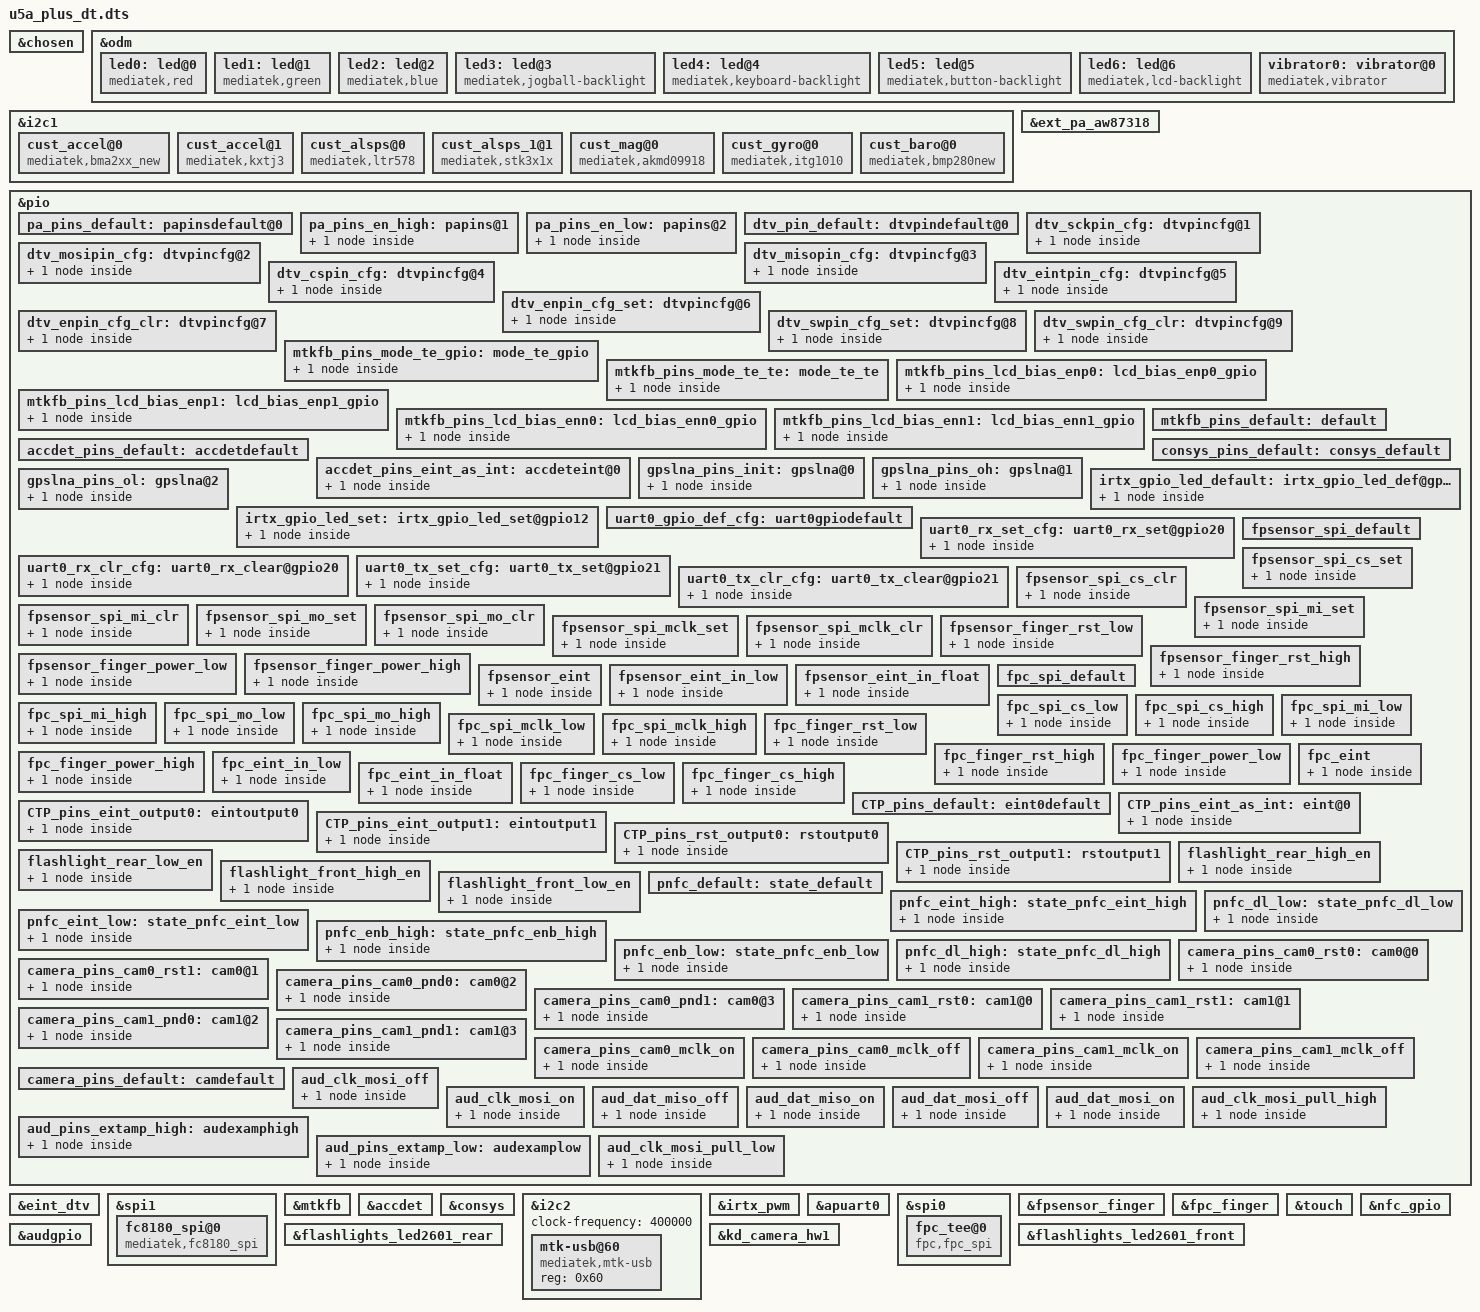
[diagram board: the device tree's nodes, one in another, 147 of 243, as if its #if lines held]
#include <generated/autoconf.h>
/dts-v1/;

#ifdef CONFIG_MTK_DTBO_FEATURE
/plugin/;
#include <dt-bindings/mmc/mt6739-msdc.h>
#include <dt-bindings/pinctrl/mt6739-pinfunc.h>
#else
#include "mt6739.dts"
#endif

/* chosen */
&chosen {
	bootargs = "console=tty0 console=ttyMT0,921600n1 root=/dev/ram initrd=0x44000000,\
0x1000000 loglevel=8 androidboot.selinux=permissive androidboot.hardware=mt6739 initcall_debug=1";
	/* fpga may has no lk, we need to specify display info here */
	/* fb buffer is reserved using this dts by memory node above */

	atag,videolfb-fb_base_l = <0x5e605000>;
	atag,videolfb-fb_base_h = <0>;
	atag,videolfb-islcmfound = <1>;
	atag,videolfb-islcm_inited = <0>;
	atag,videolfb-fps= <6000>;
	atag,videolfb-vramSize= <0x017bb000>;
	atag,videolfb-lcmname= "nt35521_hd_dsi_vdo_truly_nt50358_drv";
};

&odm {
	led0:led@0 {
		compatible = "mediatek,red";
/* Add by rongxiao.deng for 5424735 config charger indicat LED begin */
		led_mode = <3>;
		data = <2>;
/* Add by rongxiao.deng for 5424735 config charger indicat LED end */
		pwm_config = <0 0 0 0 0>;
	};
	led1:led@1 {
		compatible = "mediatek,green";
		led_mode = <0>;
		data = <1>;
		pwm_config = <0 0 0 0 0>;
	};
	led2:led@2 {
		compatible = "mediatek,blue";
		led_mode = <0>;
		data = <1>;
		pwm_config = <0 0 0 0 0>;
	};
	led3:led@3 {
		compatible = "mediatek,jogball-backlight";
		led_mode = <0>;
		data = <1>;
		pwm_config = <0 0 0 0 0>;
	};
	led4:led@4 {
		compatible = "mediatek,keyboard-backlight";
		led_mode = <0>;
		data = <1>;
		pwm_config = <0 0 0 0 0>;
	};
	led5:led@5 {
		compatible = "mediatek,button-backlight";
		led_mode = <0>;
		data = <1>;
		pwm_config = <0 0 0 0 0>;
	};
	led6:led@6 {
		compatible = "mediatek,lcd-backlight";
		led_mode = <5>;
		data = <1>;
		pwm_config = <0 2 0 0 0>;
	};
	vibrator0:vibrator@0 {
		compatible = "mediatek,vibrator";
		vib_timer = <25>;
		vib_limit = <9>;
		vib_vol= <9>;
	};
};
//Begin modified by lanying.he for XR5424729 on 2017/10/20 sensor driver
//Begin modified by lanying.he for XR5592417 on 2017/11/12 sensor 
&i2c1 {
/*  start sensor */
	cust_accel@0 {
		compatible = "mediatek,bma2xx_new";
		//i2c_num	= <1>;
		direction = <6>;
		power_id = <0xffff>;
		power_vol = <0>;
		firlen = <0>;
		is_batch_supported = <0>;
	};
	cust_accel@1 {
		compatible = "mediatek,kxtj3";
		//i2c_num	= <1>;
		direction = <6>;
		power_id = <0xffff>;
		power_vol = <0>;
		firlen = <0>;
		is_batch_supported = <0>;
	};
	cust_alsps@0 {
		compatible = "mediatek,ltr578";
		/*i2c_num = <1>;*/
		i2c_addr = <0x53 0 0 0>;
		polling_mode_ps = <0>;
		polling_mode_als = <1>;
		power_id = <0xffff>;
		power_vol = <0>;
		als_level = <0 328 861 1377 3125 7721 7767 12621 23062 28430 33274 47116 57694 57694 65535>;
		als_value = <0 133 304 502 1004 2005 3058 5005 8008 10010 12000 16000 20000 20000 20000 20000>;
		ps_threshold_high = <26>;
		ps_threshold_low = <21>;
		is_batch_supported_ps = <0>;
		is_batch_supported_als = <0>;
	};
	cust_alsps_1@1 {
		compatible = "mediatek,stk3x1x";
		/*i2c_num = <1>;*/
		i2c_addr = <0x48 0 0 0>;
		polling_mode_ps = <0>;
		polling_mode_als = <1>;
		power_id = <0xffff>;
		power_vol = <0>;
		als_level = <0 328 861 1377 3125 7721 7767 12621 23062 28430 33274 47116 57694 57694 65535>;
		als_value = <0 133 304 502 1004 2005 3058 5005 8008 10010 12000 16000 20000 20000 20000 20000>;
		ps_threshold_high = <26>;
		ps_threshold_low = <21>;
		is_batch_supported_ps = <0>;
		is_batch_supported_als = <0>;
	};
	cust_mag@0 {
		compatible			= "mediatek,akmd09918";
		//i2c_num				= <1>;
		/* i2c_addr			= <0x0C 0 0 0>; */
		direction			= <8>;
		power_id			= <0xffff>;
		power_vol			= <0>;
		/* is_batch_supported		= <0>; */
	};

	cust_gyro@0 {
		compatible			= "mediatek,itg1010";
		//i2c_num				= <1>;
		/* i2c_addr			= <0x68 0 0 0>; */
		direction			= <5>;
		power_id			= <0xffff>;
		power_vol			= <0>;
		firlen				= <0>;
		is_batch_supported		= <0>;
	};

	cust_baro@0 {
		compatible = "mediatek,bmp280new";
		i2c_num = <1>;
		/* i2c_addr = <0x77 0 0 0>; */
		direction = <0>;
		power_id = <0xffff>;
		power_vol = <0>;
		firlen = <32>;
		is_batch_supported = <0>;
	};
/* end sensor */
};

/* Begin added by jinhui.duan.hz for task 5597245 on 20171117,add aw87318 external audio pa driver. */
&ext_pa_aw87318 {
	deb-gpios = <&pio 24 0>;
	pinctrl-names = "pin_default", "en_pin_high", "en_pin_low";
	pinctrl-0 = <&pa_pins_default>;
	pinctrl-1 = <&pa_pins_en_high>;
	pinctrl-2 = <&pa_pins_en_low>;
	status = "okay";
};

&pio {
	pa_pins_default: papinsdefault@0 {
	};
	pa_pins_en_high: papins@1 {
		pins_cmd_dat {
			pins = <PINMUX_GPIO24__FUNC_GPIO24>;
			slew-rate = <1>;
			bias-disable;
			output-high;
		};
	};
	pa_pins_en_low: papins@2 {
		pins_cmd_dat {
			pins = <PINMUX_GPIO24__FUNC_GPIO24>;
			slew-rate = <1>;
			bias-disable;
			output-low;
		};
	};
};
/* End added by jinhui.duan.hz for task 5597245 on 20171117,add aw87318 external audio pa driver. */

/* Begin added by shiqiang.chen.hz for task 5597245 on 20171117,add add fc8180 dtv driver. */
&eint_dtv {
	pinctrl-names = "default", "sck_cfg", "mosi_cfg", "miso_cfg", "cs_cfg", "eint_cfg",
                        "en_cfg_set", "en_cfg_clr", "sw_cfg_set", "sw_cfg_clr";
	pinctrl-0 = <&dtv_pin_default>;
	pinctrl-1 = <&dtv_sckpin_cfg>;
	pinctrl-2 = <&dtv_mosipin_cfg>;
	pinctrl-3 = <&dtv_misopin_cfg>;
	pinctrl-4 = <&dtv_cspin_cfg>;
	pinctrl-5 = <&dtv_eintpin_cfg>;
	pinctrl-6 = <&dtv_enpin_cfg_set>;
	pinctrl-7 = <&dtv_enpin_cfg_clr>;
	pinctrl-8 = <&dtv_swpin_cfg_set>;
	pinctrl-9 = <&dtv_swpin_cfg_clr>;
	status = "okay";
};

&pio {
	dtv_pin_default: dtvpindefault@0 {
	};
	dtv_sckpin_cfg: dtvpincfg@1 {
		pins_cmd_dat {
			pins = <PINMUX_GPIO17__FUNC_SPI1_A_CLK>;
		};
	};
	dtv_mosipin_cfg: dtvpincfg@2 {
		pins_cmd_dat {
			pins = <PINMUX_GPIO19__FUNC_SPI1_A_MO>;
		};
	};
	dtv_misopin_cfg: dtvpincfg@3 {
		pins_cmd_dat {
			pins = <PINMUX_GPIO18__FUNC_SPI1_A_MI>;
		};
	};
	dtv_cspin_cfg: dtvpincfg@4 {
		pins_cmd_dat {
			pins = <PINMUX_GPIO16__FUNC_SPI1_A_CSB>;
		};
	};
	dtv_eintpin_cfg: dtvpincfg@5 {
		pins_cmd_dat {
			pins = <PINMUX_GPIO13__FUNC_GPIO13>;
			slew-rate = <0>;
			bias-disable;
		};
	};
	dtv_enpin_cfg_set: dtvpincfg@6 {
		pins_cmd_dat {
			pins = <PINMUX_GPIO2__FUNC_GPIO2>;
			slew-rate = <1>;
			bias-disable;
			output-high;
		};
	};
	dtv_enpin_cfg_clr: dtvpincfg@7 {
		pins_cmd_dat {
			pins = <PINMUX_GPIO2__FUNC_GPIO2>;
			slew-rate = <1>;
			bias-disable;
			output-low;
		};
	};
	dtv_swpin_cfg_set: dtvpincfg@8 {
		pins_cmd_dat {
			pins = <PINMUX_GPIO28__FUNC_GPIO28>;
			slew-rate = <1>;
			bias-disable;
			output-high;
		};
	};
	dtv_swpin_cfg_clr: dtvpincfg@9 {
		pins_cmd_dat {
			pins = <PINMUX_GPIO28__FUNC_GPIO28>;
			slew-rate = <1>;
			bias-disable;
			output-low;
		};
	};
};

&spi1 {
	#address-cells = <1>;
	#size-cells = <0>;

	fc8180_spi@0 {
		compatible = "mediatek,fc8180_spi";
		reg = <0>;
		spi-max-frequency = <12000000>;
		//netlink-event = <31>;
		status = "okay";
	};
};
/* End added by shiqiang.chen.hz for task 5597245 on 20171117,add add fc8180 dtv driver. */

/* DISPSYS GPIO standardization add by llf for LCD bias */
&pio {

	mtkfb_pins_mode_te_gpio: mode_te_gpio {
		pins_cmd_dat {
			pins = <PINMUX_GPIO84__FUNC_GPIO84>;
		};
	};

	mtkfb_pins_mode_te_te: mode_te_te {
		pins_cmd_dat {
			pins = <PINMUX_GPIO84__FUNC_DSI_TE>;
		};
	};

	mtkfb_pins_lcd_bias_enp0: lcd_bias_enp0_gpio {
		pins_cmd_dat {
			pins = <PINMUX_GPIO28__FUNC_GPIO28>;
			slew-rate = <1>;
			bias-pull-up = <00>;
			output-low;
		};
	};

	mtkfb_pins_lcd_bias_enp1: lcd_bias_enp1_gpio {
		pins_cmd_dat {
			pins = <PINMUX_GPIO28__FUNC_GPIO28>;
			slew-rate = <1>;
			bias-pull-up = <00>;
			output-high;
		};
	};

	mtkfb_pins_lcd_bias_enn0: lcd_bias_enn0_gpio {
                   pins_cmd_dat {
			pins = <PINMUX_GPIO122__FUNC_GPIO122>;
			slew-rate = <1>;
			bias-pull-up = <00>;
			output-low;
                   };
         };

         mtkfb_pins_lcd_bias_enn1: lcd_bias_enn1_gpio {
                   pins_cmd_dat {
			pins = <PINMUX_GPIO122__FUNC_GPIO122>;
			slew-rate = <1>;
			bias-pull-up = <00>;
			output-high;
                   };
         };

	mtkfb_pins_default: default {
	};
};

&mtkfb {
	pinctrl-names = "default", "mode_te_gpio", "mode_te_te",  "lcd_bias_enp0", 
	"lcd_bias_enp1","lcd_bias_enn0", "lcd_bias_enn1";
	pinctrl-0 = <&mtkfb_pins_default>;
	pinctrl-1 = <&mtkfb_pins_mode_te_gpio>;
	pinctrl-2 = <&mtkfb_pins_mode_te_te>;
	pinctrl-3 = <&mtkfb_pins_lcd_bias_enp0>;
	pinctrl-4 = <&mtkfb_pins_lcd_bias_enp1>;
	pinctrl-5 = <&mtkfb_pins_lcd_bias_enn0>;
	pinctrl-6 = <&mtkfb_pins_lcd_bias_enn1>;
	status = "okay";
};/* DISPSYS GPIO standardization add by llf for LCD bias end */


/* accdet start */
&accdet {
	/* accdet micbias voltage: 0x07,2.7v;0x05,2.5v;0x02,1.9v */
	accdet-mic-vol = <6>;
	headset-mode-setting = <0x500 0x500 1 0x1f0 0x800 0x800 0x20 0x44>;
	/* Begin Modified by meng.zhang for task 5424730 on 2017/10/21 */
	accdet-plugout-debounce = <20>;
	/*1:ACC mode, 2:low cost without in bias, 6:low cost with in bias*/
	accdet-mic-mode = <1>;
	/* End Modified by meng.zhang for task 5424730 on 2017/10/21 */
	/* eint_level_trigger: 8,LEVEL_LOW(default);4,LEVEL_HIGH;others,LEVEL_LOW */
	headset-eint-level-pol = <8>;
	/*0--MD_MAX--UP_MAX--DW_MAX*/
	headset-three-key-threshold = <0 80 220 400>;
	headset-three-key-threshold-CDD = <0 121 192 600>;
	/*0--MD_MAX--VOICE_MAX--UP_MAX--DW_MAX*/
	headset-four-key-threshold = <0 58 121 192 400>;
	/* ACCDET GPIO standardization ACC mode no use */
	pinctrl-names = "default", "state_eint_as_int";
	pinctrl-0 = <&accdet_pins_default>;
	pinctrl-1 = <&accdet_pins_eint_as_int>;
	status = "okay";
};
&pio {
	accdet_pins_default: accdetdefault {
	};
	accdet_pins_eint_as_int: accdeteint@0 {
		pins_cmd_dat {
			/* Begin Modified by meng.zhang for task 5424730 on 2017/10/21 */
			pins = <PINMUX_GPIO11__FUNC_GPIO11>;
			/* End Modified by meng.zhang for task 5424730 on 2017/10/21 */
			slew-rate = <0>;
			bias-disable;
		};
	};
};
/* accdet end */
/* CONSYS GPIO standardization */
&pio {
	consys_pins_default: consys_default {
	};
	gpslna_pins_init: gpslna@0 {
		pins_cmd_dat {
			pins = <PINMUX_GPIO118__FUNC_GPIO118>;
			slew-rate = <0>;
			bias-disable;
			output-low;
		};
	};
	gpslna_pins_oh: gpslna@1 {
		pins_cmd_dat {
			pins = <PINMUX_GPIO118__FUNC_GPIO118>;
			slew-rate = <1>;
			output-high;
		};
	};
	gpslna_pins_ol: gpslna@2 {
		pins_cmd_dat {
			pins = <PINMUX_GPIO118__FUNC_GPIO118>;
			slew-rate = <1>;
			output-low;
		};
	};
};
&consys {
	pinctrl-names = "default", "gps_lna_state_init", "gps_lna_state_oh", "gps_lna_state_ol";
	pinctrl-0 = <&consys_pins_default>;
	pinctrl-1 = <&gpslna_pins_init>;
	pinctrl-2 = <&gpslna_pins_oh>;
	pinctrl-3 = <&gpslna_pins_ol>;
	status = "okay";
};
&i2c2 {
	#address-cells = <1>;
	#size-cells = <0>;
	clock-frequency = <400000>;

	mtk-usb@60 {
		compatible = "mediatek,mtk-usb";
		reg = <0x60>;
		status = "okay";
	};
};

/* IRTX GPIO Start */
&irtx_pwm {
	pinctrl-names = "irtx_gpio_led_default", "irtx_gpio_led_set";
	pinctrl-0 = <&irtx_gpio_led_default>;
	pinctrl-1 = <&irtx_gpio_led_set>;
	status = "okay";
};
&pio {
	/* IRTX GPIO Settings -Start */
	/* default: GPIO0, output, high */
	irtx_gpio_led_default:irtx_gpio_led_def@gpio12 {
		pins_cmd_dat {
			pins = <PINMUX_GPIO12__FUNC_GPIO12>;
			slew-rate = <1>;
			bias-disable;
			output-low;
			input-schmitt-enable = <0>;
		};
	};

	irtx_gpio_led_set:irtx_gpio_led_set@gpio12 {
		pins_cmd_dat {
			pins = <PINMUX_GPIO12__FUNC_PWM1>;
			slew-rate = <1>;
			output-high;
		};
	};
}; /* IRTX GPIO Settings -End */

/* UART GPIO */
&apuart0 {
	pinctrl-names = "uart0_gpio_default",
			"uart0_rx_set",
			"uart0_rx_clear",
			"uart0_tx_set",
			"uart0_tx_clear";
	pinctrl-0 = <&uart0_gpio_def_cfg>;
	pinctrl-1 = <&uart0_rx_set_cfg>;
	pinctrl-2 = <&uart0_rx_clr_cfg>;
	pinctrl-3 = <&uart0_tx_set_cfg>;
	pinctrl-4 = <&uart0_tx_clr_cfg>;
	status = "okay";
};

&pio {
	/* UART GPIO Settings - Start */
	/* UART0: rx set, rx clear, tx clear, tx clear*/
	uart0_gpio_def_cfg:uart0gpiodefault {

	};
	uart0_rx_set_cfg:uart0_rx_set@gpio20 {
		pins_cmd_dat {
			pins = <PINMUX_GPIO20__FUNC_UART0RX>;
		};
	};
	uart0_rx_clr_cfg:uart0_rx_clear@gpio20 {
		pins_cmd_dat {
			pins = <PINMUX_GPIO20__FUNC_GPIO20>;
			slew-rate = <1>;
			output-high;
		};
	};
	uart0_tx_set_cfg:uart0_tx_set@gpio21 {
		pins_cmd_dat {
			pins = <PINMUX_GPIO21__FUNC_UART0TX>;
		};
	};
	uart0_tx_clr_cfg:uart0_tx_clear@gpio21 {
		pins_cmd_dat {
			pins = <PINMUX_GPIO21__FUNC_GPIO21>;
			slew-rate = <1>;
			output-high;
		};
	};
};/* UART GPIO end */

/* FINGERPRINT start */
/*Begin added by zhihua.fang for u5a fpsensor on 2017/11/1*/

//according to fps fae mtxxx.dts
&spi0 {
	#address-cells = <1>;     
	#size-cells = <0>;
   fpc_tee@0 {
       		compatible = "fpc,fpc_spi";
       		reg = <0>;
       		spi-max-frequency = <10000000>;
       		netlink-event = <31>;
			fpc,enable-wakeup;
       		status = "okay";
    	};
};

&fpsensor_finger {

        pinctrl-names = "fpsensor_spi_default", "fpsensor_spi_cs_set","fpsensor_spi_cs_clr","fpsensor_spi_mi_set","fpsensor_spi_mi_clr",
			"fpsensor_spi_mo_set","fpsensor_spi_mo_clr","fpsensor_spi_mclk_set","fpsensor_spi_mclk_clr",
			"fpsensor_finger_rst_low","fpsensor_finger_rst_high","fpsensor_finger_power_low","fpsensor_finger_power_high",
	                "fpsensor_eint","fpsensor_eint_in_low","fpsensor_eint_in_float";	
	pinctrl-0 = <&fpsensor_spi_default>;
	pinctrl-1 = <&fpsensor_spi_cs_set>;
	pinctrl-2 = <&fpsensor_spi_cs_clr>;
	pinctrl-3 = <&fpsensor_spi_mi_set>;
	pinctrl-4 = <&fpsensor_spi_mi_clr>;
	pinctrl-5 = <&fpsensor_spi_mo_set>;
	pinctrl-6 = <&fpsensor_spi_mo_clr>;
	pinctrl-7 = <&fpsensor_spi_mclk_set>;
	pinctrl-8 = <&fpsensor_spi_mclk_clr>;	
	pinctrl-9 = <&fpsensor_finger_rst_low>;
	pinctrl-10 = <&fpsensor_finger_rst_high>;
	pinctrl-11 = <&fpsensor_finger_power_low>;
	pinctrl-12 = <&fpsensor_finger_power_high>;	
	pinctrl-13 = <&fpsensor_eint>;
	pinctrl-14 = <&fpsensor_eint_in_low>;
	pinctrl-15 = <&fpsensor_eint_in_float>;
	status = "okay";
};

&pio {
	fpsensor_spi_default: fpsensor_spi_default {
	};

	fpsensor_spi_cs_set: fpsensor_spi_cs_set {
		pins_cmd_dat {
                        pins = <PINMUX_GPIO31__FUNC_SPI0_A_CSB>;
			output-enable;
		};
	};
	fpsensor_spi_cs_clr: fpsensor_spi_cs_clr {
		pins_cmd_dat {
                        pins = <PINMUX_GPIO31__FUNC_GPIO31>;
			slew-rate = <1>;
			output-high;
		};
	};	

	fpsensor_spi_mi_set: fpsensor_spi_mi_set {
		pins_cmd_dat {
                        pins = <PINMUX_GPIO33__FUNC_SPI0_A_MI>;
			input-enable;
		};
		
	};
	fpsensor_spi_mi_clr: fpsensor_spi_mi_clr {
		pins_cmd_dat {
                        pins = <PINMUX_GPIO33__FUNC_GPIO33>;
			slew-rate = <1>;
			output-high;
		};
	};	

	fpsensor_spi_mo_set: fpsensor_spi_mo_set {
		pins_cmd_dat {
                        pins = <PINMUX_GPIO34__FUNC_SPI0_A_MO>;
			input-enable;
		};

	};
	fpsensor_spi_mo_clr: fpsensor_spi_mo_clr {
		pins_cmd_dat {
			pins = <PINMUX_GPIO34__FUNC_GPIO34>;
			slew-rate = <1>;
			output-low;
		}; 

	};	

	fpsensor_spi_mclk_set: fpsensor_spi_mclk_set {
		pins_cmd_dat {
			pins = <PINMUX_GPIO32__FUNC_SPI0_A_CLK>;
			input-enable;
		};
	
	};
	fpsensor_spi_mclk_clr: fpsensor_spi_mclk_clr {
		pins_cmd_dat {
			pins = <PINMUX_GPIO32__FUNC_GPIO32>;
			slew-rate = <1>;
			output-low;
		};

	};	

	fpsensor_finger_rst_low: fpsensor_finger_rst_low {
		pins_cmd_dat {
			pins = <PINMUX_GPIO25__FUNC_GPIO25>;
			slew-rate = <1>;
			output-low;
		};
	};
	fpsensor_finger_rst_high: fpsensor_finger_rst_high {
		pins_cmd_dat {
			pins = <PINMUX_GPIO25__FUNC_GPIO25>;
			slew-rate = <1>;
			output-high;
		};
	};	
	fpsensor_finger_power_low: fpsensor_finger_power_low {
			pins_cmd_dat {
			pins = <PINMUX_GPIO26__FUNC_GPIO26>;
			slew-rate = <1>;
			output-low;
		};
	};
	fpsensor_finger_power_high: fpsensor_finger_power_high {
		pins_cmd_dat {
			pins = <PINMUX_GPIO26__FUNC_GPIO26>;
			slew-rate = <1>;
			output-high;
		};		
	};	
	fpsensor_eint: fpsensor_eint {
		pins_cmd_dat {
			pins = <PINMUX_GPIO51__FUNC_GPIO51>;
			slew-rate = <0>;
			bias-disable;
		};
	};
	fpsensor_eint_in_low: fpsensor_eint_in_low {
		pins_cmd_dat {
			pins = <PINMUX_GPIO51__FUNC_GPIO51>;
			slew-rate = <0>;
			bias-pull-down = <00>;
		};
	};
	fpsensor_eint_in_float: fpsensor_eint_in_float {
		pins_cmd_dat {
			pins = <PINMUX_GPIO51__FUNC_GPIO51>;
			slew-rate = <0>;
			bias-disable;
		};
	};		
};
/*End added by zhihua.fang for u5a fpsensor on 2017/11/17 */
/* FINGERPRINT END */

/* FINGERPRINT start */
/*Begin added by zhihua.fang for u5a fpsensor on 2017/11/1*/
//according to fps fae mtxxx.dts
/*
&spi0 {
	#address-cells = <1>;     
	#size-cells = <0>;
   fpc_tee@0 {
       		compatible = "fpc,fpc_spi";
       		reg = <0>;
		fpc,enable-wakeup;
       		spi-max-frequency = <10000000>;
       		netlink-event = <31>;
       		status = "okay";
    	};
};
*/
&fpc_finger {
        pinctrl-names = "fpc_spi_default", "fpc_spi_cs_low","fpc_spi_cs_high","fpc_spi_mi_low","fpc_spi_mi_high",
			"fpc_spi_mo_low","fpc_spi_mo_high","fpc_spi_mclk_low","fpc_spi_mclk_high",
			"fpc_finger_rst_low","fpc_finger_rst_high","fpc_finger_power_low","fpc_finger_power_high",
                        "fpc_eint","fpc_eint_in_low","fpc_eint_in_float","fpc_finger_cs_low","fpc_finger_cs_high";	
	pinctrl-0 = <&fpc_spi_default>;
        pinctrl-1 = <&fpc_spi_cs_low>;
	pinctrl-2 = <&fpc_spi_cs_high>;
	pinctrl-3 = <&fpc_spi_mi_low>;
	pinctrl-4 = <&fpc_spi_mi_high>;
	pinctrl-5 = <&fpc_spi_mo_low>;
	pinctrl-6 = <&fpc_spi_mo_high>;
	pinctrl-7 = <&fpc_spi_mclk_low>;
	pinctrl-8 = <&fpc_spi_mclk_high>;	
	pinctrl-9 = <&fpc_finger_rst_low>;
	pinctrl-10 = <&fpc_finger_rst_high>;
	pinctrl-11 = <&fpc_finger_power_low>;
	pinctrl-12 = <&fpc_finger_power_high>;	
	pinctrl-13 = <&fpc_eint>;
	pinctrl-14 = <&fpc_eint_in_low>;
	pinctrl-15 = <&fpc_eint_in_float>;
	pinctrl-16 = <&fpc_finger_cs_low>;
	pinctrl-17 = <&fpc_finger_cs_high>;
	status = "okay";
};

&pio {
	fpc_spi_default: fpc_spi_default {
	};

	fpc_spi_cs_low: fpc_spi_cs_low {
		pins_cmd_dat {
			pins = <PINMUX_GPIO31__FUNC_GPIO31>;
			slew-rate = <1>;
			output-low;
                };
	};
	fpc_spi_cs_high: fpc_spi_cs_high {
		pins_cmd_dat {
                        pins = <PINMUX_GPIO31__FUNC_GPIO31>;
			slew-rate = <1>;
			output-high;
		};
	};	

	fpc_spi_mi_low: fpc_spi_mi_low {
		pins_cmd_dat {
			pins = <PINMUX_GPIO33__FUNC_SPI0_A_MI>;  //PINMUX_GPIO33__FUNC_SPI0_A_MI//
			slew-rate = <0>;
			bias-pull-up = <00>;
		};
		
	};
	fpc_spi_mi_high: fpc_spi_mi_high {
		pins_cmd_dat {
			pins = <PINMUX_GPIO33__FUNC_SPI0_A_MI>;
			bias-disable;
		};
	};	
	fpc_spi_mo_low: fpc_spi_mo_low {
		pins_cmd_dat {
			pins = <PINMUX_GPIO34__FUNC_SPI0_A_MO>;
			slew-rate = <1>;
			output-low;
		};

	};
	fpc_spi_mo_high: fpc_spi_mo_high {
		pins_cmd_dat {
			pins = <PINMUX_GPIO34__FUNC_SPI0_A_MO>; //PINMUX_GPIO34__FUNC_SPI0_A_MO
			slew-rate = <1>;
			output-high;
		}; 

	};

	fpc_spi_mclk_low: fpc_spi_mclk_low {
		pins_cmd_dat {
			pins = <PINMUX_GPIO32__FUNC_SPI0_A_CLK>;
			slew-rate = <1>;
			output-low;
		};
	
	};
	fpc_spi_mclk_high: fpc_spi_mclk_high {
		pins_cmd_dat {
			pins = <PINMUX_GPIO32__FUNC_SPI0_A_CLK>;
			slew-rate = <1>;
			output-high;
		};

	};	

	fpc_finger_rst_low: fpc_finger_rst_low {
		pins_cmd_dat {
			pins = <PINMUX_GPIO25__FUNC_GPIO25>;
			slew-rate = <1>;
			output-low;
		};
	};
	fpc_finger_rst_high: fpc_finger_rst_high {
		pins_cmd_dat {
			pins = <PINMUX_GPIO25__FUNC_GPIO25>;
			slew-rate = <1>;
			output-high;
		};
	};	
	fpc_finger_power_low: fpc_finger_power_low {
			pins_cmd_dat {
			pins = <PINMUX_GPIO26__FUNC_GPIO26>;
			slew-rate = <1>;
			output-low;
		};
	};
	fpc_finger_power_high: fpc_finger_power_high {
		pins_cmd_dat {
			pins = <PINMUX_GPIO26__FUNC_GPIO26>;
			slew-rate = <1>;
			output-high;
		};		
	};	
	fpc_eint: fpc_eint {
		pins_cmd_dat {
			pins = <PINMUX_GPIO51__FUNC_GPIO51>;
			slew-rate = <0>;
			bias-disable;
		};
	};
	fpc_eint_in_low: fpc_eint_in_low {
		pins_cmd_dat {
			pins = <PINMUX_GPIO51__FUNC_GPIO51>;
			slew-rate = <0>;
			bias-pull-down = <00>;
		};
	};
	fpc_eint_in_float: fpc_eint_in_float {
		pins_cmd_dat {
			pins = <PINMUX_GPIO51__FUNC_GPIO51>;
			slew-rate = <0>;
			bias-disable;
		};
	};
	fpc_finger_cs_low: fpc_finger_cs_low {
		pins_cmd_dat {
			pins = <PINMUX_GPIO31__FUNC_GPIO31>;
			slew-rate = <1>;
			output-low;
		};
	};
	fpc_finger_cs_high: fpc_finger_cs_high {
		pins_cmd_dat {
			pins = <PINMUX_GPIO31__FUNC_GPIO31>;
			slew-rate = <1>;
			output-high;
		};
	};	
};
/*End added by qiyang.yan for fpc on 2017/12/19 */
/* FINGERPRINT END */

/* TOUCH start */
/* Modify by llf for NEW CTP drivers*/
&touch {
	tpd-resolution = <480 960>;
	use-tpd-button = <1>;
	tpd-key-num = <3>;
	tpd-key-local= <158 172 139>;
/*** begin: modified by liuhe.zhong for cts test on 2018.02.11 ***/
	tpd-key-dim-local = <81 905 106 55 187 905 106 55 293 905 106 55>;
/*** end:   modified by liuhe.zhong for cts test on 2018.02.11 ***/
	tpd-max-touch-num = <2>;
	tpd-filter-enable = <0>;
	tpd-filter-pixel-density = <124>;
	tpd-filter-custom-prameters = <0 0 0 0 0 0 0 0 0 0 0 0>;
	tpd-filter-custom-speed = <0 0 0>;
	pinctrl-names = "default", "state_eint_as_int", "state_eint_output0", "state_eint_output1",
		"state_rst_output0", "state_rst_output1";
	pinctrl-0 = <&CTP_pins_default>;
	pinctrl-1 = <&CTP_pins_eint_as_int>;
	pinctrl-2 = <&CTP_pins_eint_output0>;
	pinctrl-3 = <&CTP_pins_eint_output1>;
	pinctrl-4 = <&CTP_pins_rst_output0>;
	pinctrl-5 = <&CTP_pins_rst_output1>;
/*** begin: added by liuhe.zhong for board id hardware information on 2018.01.03 ***/
	boardid-gpio103 = <&pio 103 0>;
	boardid-gpio104 = <&pio 104 0>;
	boardid-gpio105 = <&pio 105 0>;
/*** end:   added by liuhe.zhong for board id hardware information on 2018.01.03 ***/
	status = "okay";
};
&pio {
	CTP_pins_default: eint0default {
	};
	CTP_pins_eint_as_int: eint@0 {
		pins_cmd_dat {
			pins = <PINMUX_GPIO6__FUNC_GPIO6>;
			slew-rate = <0>;
			bias-disable;
		};
	};
	CTP_pins_eint_output0: eintoutput0 {
		pins_cmd_dat {
			pins = <PINMUX_GPIO6__FUNC_GPIO6>;
			slew-rate = <1>;
			output-low;
		};
	};
	CTP_pins_eint_output1: eintoutput1 {
		pins_cmd_dat {
			pins = <PINMUX_GPIO6__FUNC_GPIO6>;
			slew-rate = <1>;
			output-high;
		};
	};
	CTP_pins_rst_output0: rstoutput0 {
		pins_cmd_dat {
			pins = <PINMUX_GPIO119__FUNC_GPIO119>;
			slew-rate = <1>;
			output-low;
		};
	};
	CTP_pins_rst_output1: rstoutput1 {
		pins_cmd_dat {
			pins = <PINMUX_GPIO119__FUNC_GPIO119>;
			slew-rate = <1>;
			output-high;
		};
	};
};
/* TOUCH end */
//Begin added by zhanyong.yin for XR5301378 on 2017/10/19
/*flashlight*/
#if 0
&flashlights_lm3642 {
	pinctrl-names = "front_flash_high", "front_flash_low","front_torch_high", "front_torch_low";
//Begin modified by shiqiang.chen.hz on 20171230, temporary modification for DTV
	//pinctrl-0 = <&hwen_flash_high_en>;
	//pinctrl-1 = <&hwen_flash_low_en>;
	//pinctrl-2 = <&hwen_torch_high_en>;
	//pinctrl-3 = <&hwen_torch_low_en>;
//End modified by shiqiang.chen.hz on 20171230, temporary modification for DTV
	status = "okay";
};
&pio {
	hwen_flash_high_en: hwen_flash_high_en {
		pins_cmd_dat {
			pins = <PINMUX_GPIO18__FUNC_GPIO18>;
			slew-rate = <1>;
			output-high;
		};
	};
	hwen_flash_low_en: hwen_flash_low_en {
		pins_cmd_dat {
			pins = <PINMUX_GPIO18__FUNC_GPIO18>;
			slew-rate = <1>;
			output-low;
		};
	};
	hwen_torch_high_en: hwen_torch_high_en {
		pins_cmd_dat {
			pins = <PINMUX_GPIO19__FUNC_GPIO19>;
			slew-rate = <1>;
			output-high;
		};
	};
	hwen_torch_low_en: hwen_torch_low_en {
		pins_cmd_dat {
			pins = <PINMUX_GPIO19__FUNC_GPIO19>;
			slew-rate = <1>;
			output-low;
		};
	};
};
/*flashlight*/
#endif

/* begin, add by Jimfu for main flashlight on 2017-12-28*/

/*flashlight*/
&flashlights_led2601_rear {
	pinctrl-names = "rear_flashlight_high", "rear_flashlight_low";
	pinctrl-0 = <&flashlight_rear_high_en>;
	pinctrl-1 = <&flashlight_rear_low_en>;
	status = "okay";
};
&pio {
	/*	reat flahlitht	*/
	flashlight_rear_high_en: flashlight_rear_high_en {
		pins_cmd_dat {
			pins = <PINMUX_GPIO10__FUNC_GPIO10>;
			slew-rate = <1>;
			output-high;
		};
	};
	flashlight_rear_low_en: flashlight_rear_low_en {
		pins_cmd_dat {
			pins = <PINMUX_GPIO10__FUNC_GPIO10>;
			slew-rate = <1>;
			output-low;
		};
	};
};

&flashlights_led2601_front {
	pinctrl-names = "front_flashlight_high", "front_flashlight_low";
	pinctrl-0 = <&flashlight_front_high_en>;
	pinctrl-1 = <&flashlight_front_low_en>;
	status = "okay";
};
&pio {
	
	/*	front flashlight	*/
	flashlight_front_high_en: flashlight_front_high_en {
		pins_cmd_dat {
			pins = <PINMUX_GPIO1__FUNC_GPIO1>;
			slew-rate = <1>;
			output-high;
		};
	};
	flashlight_front_low_en: flashlight_front_low_en {
		pins_cmd_dat {
			pins = <PINMUX_GPIO1__FUNC_GPIO1>;
			slew-rate = <1>;
			output-low;
		};
	};
};
/* end, add by Jimfu for main flashlight on 2017-12-28*/

#if 0
&flashlights_led191 {
	pinctrl-names = "hwen_high", "hwen_low","hwen_high1", "hwen_low1";
//Begin modified by shiqiang.chen.hz on 20171230, temporary modification for DTV
	//pinctrl-0 = <&hwen_high_en>;
	//pinctrl-1 = <&hwen_low_en>;
//End modified by shiqiang.chen.hz on 20171230, temporary modification for DTV
	pinctrl-2 = <&hwen_high_en1>;
	pinctrl-3 = <&hwen_low_en1>;
	status = "okay";
};
&pio {
	hwen_high_en: hwen_high_en {
		pins_cmd_dat {
			pins = <PINMUX_GPIO13__FUNC_GPIO13>;
			slew-rate = <1>;
			output-high;
		};
	};
	hwen_low_en: hwen_low_en {
		pins_cmd_dat {
			pins = <PINMUX_GPIO13__FUNC_GPIO13>;
			slew-rate = <1>;
			output-low;
		};
	};
	hwen_high_en1: hwen_high_en1 {
		pins_cmd_dat {
			pins = <PINMUX_GPIO136__FUNC_GPIO136>;
			slew-rate = <1>;
			output-high;
		};
	};
	hwen_low_en1: hwen_low_en1 {
		pins_cmd_dat {
			pins = <PINMUX_GPIO136__FUNC_GPIO136>;
			slew-rate = <1>;
			output-low;
		};
	};
};
//End added by zhanyong.yin for XR5301378 on 2017/10/19
#endif

/* NFC start */
/*begin add by zhihua.fang for u5a plus  on 2017.08.17 */
&nfc_gpio {
	eint_intr_gpio = <14>; /* direct defined GPIO num */
	eint_intr_gpio_named = <&pio 14 0x0>; /* named GPIO */
	pinctrl-names = "default", "nfc_eint_high", "nfc_eint_low", "nfc_enb_high", "nfc_enb_low", "nfc_dl_high", "nfc_dl_low";
	pinctrl-0 = <&pnfc_default>;
	pinctrl-1 = <&pnfc_eint_high>;
	pinctrl-2 = <&pnfc_eint_low>;
	pinctrl-3 = <&pnfc_enb_high>;
	pinctrl-4 = <&pnfc_enb_low>;
	pinctrl-5 = <&pnfc_dl_high>;
	pinctrl-6 = <&pnfc_dl_low>;
	status = "okay";
};

&pio {
	pnfc_default: state_default {
	};

	pnfc_eint_high: state_pnfc_eint_high {
		pins_cmd_dat {
			pins = <PINMUX_GPIO14__FUNC_GPIO14>;
			slew-rate = <0>;
			bias-pull-up = <00>;
		};
	};

	pnfc_eint_low: state_pnfc_eint_low {
		pins_cmd_dat {
			pins = <PINMUX_GPIO14__FUNC_GPIO14>;
			slew-rate = <0>;
			bias-pull-down = <00>;
		};
	};

	pnfc_enb_high: state_pnfc_enb_high {
		pins_cmd_dat {
			pins = <PINMUX_GPIO5__FUNC_GPIO5>;
			slew-rate = <1>;
			output-high;
		};
	};

	pnfc_enb_low: state_pnfc_enb_low {
		pins_cmd_dat {
			pins = <PINMUX_GPIO5__FUNC_GPIO5>;
			slew-rate = <1>;
			output-low;
		};
	};

	pnfc_dl_high: state_pnfc_dl_high {
		pins_cmd_dat {
			pins = <PINMUX_GPIO3__FUNC_GPIO3>;
			slew-rate = <1>;
			output-high;
		};
	};

	pnfc_dl_low: state_pnfc_dl_low {
		pins_cmd_dat {
			pins = <PINMUX_GPIO3__FUNC_GPIO3>;
			slew-rate = <1>;
			output-low;
		};
	};
};
/* End Modified by meng.zhang for task 5424739 on 2017/10/21 */
/* NFC end */

/* CAMERA GPIO standardization */
&pio {
	camera_pins_cam0_rst0: cam0@0 {
		pins_cmd_dat {
			pins = <PINMUX_GPIO29__FUNC_GPIO29>;
			slew-rate = <1>; /*direction 0:in, 1:out*/
			output-low;/*direction out used only. output_low or high*/
		};
	};
	camera_pins_cam0_rst1: cam0@1 {
		pins_cmd_dat {
			pins = <PINMUX_GPIO29__FUNC_GPIO29>;
			slew-rate = <1>;
			output-high;
		};
	};
	camera_pins_cam0_pnd0: cam0@2 {
		pins_cmd_dat {
			pins = <PINMUX_GPIO30__FUNC_GPIO30>;
			slew-rate = <1>;
			output-low;
		};
	};
	camera_pins_cam0_pnd1: cam0@3 {
		pins_cmd_dat {
			pins = <PINMUX_GPIO30__FUNC_GPIO30>;
			slew-rate = <1>;
			output-high;
		};
	};
//Begin added by zhanyong.yin for XR5301378 on 2017/10/19
	/*camera_pins_cam0_af0: cam0@4 {
		pins_cmd_dat {
			pins = <PINMUX_GPIO105__FUNC_GPIO105>;
			slew-rate = <1>;
			output-low;
		};
	};
	camera_pins_cam0_af1: cam0@5 {
		pins_cmd_dat {
			pins = <PINMUX_GPIO105__FUNC_GPIO105>;
			slew-rate = <1>;
			output-high;
		};
	};*/
//End added by zhanyong.yin for XR5301378 on 2017/10/19
	camera_pins_cam1_rst0: cam1@0 {
		pins_cmd_dat {
			pins = <PINMUX_GPIO22__FUNC_GPIO22>;
			slew-rate = <1>; /*direction 0:in, 1:out*/
			output-low;/*direction out used only. output_low or high*/
		};
	};
	camera_pins_cam1_rst1: cam1@1 {
		pins_cmd_dat {
			pins = <PINMUX_GPIO22__FUNC_GPIO22>;
			slew-rate = <1>;
			output-high;
		};
	};
	camera_pins_cam1_pnd0: cam1@2 {
		pins_cmd_dat {
			pins = <PINMUX_GPIO23__FUNC_GPIO23>;
			slew-rate = <1>;
			output-low;
		};
	};
	camera_pins_cam1_pnd1: cam1@3 {
		pins_cmd_dat {
			pins = <PINMUX_GPIO23__FUNC_GPIO23>;
			slew-rate = <1>;
			output-high;
		};
	};
        //begin, modify by zhijun.fu for  avoid p-sensor interrupt on 2017-12-28
	/*camera_pins_cam_ldo_sub_vcamd_0: cam1@vcamd0 {
		pins_cmd_dat {
			pins = <PINMUX_GPIO9__FUNC_GPIO9>;
			slew-rate = <1>;
			output-low;
		};
	};
	camera_pins_cam_ldo_sub_vcamd_1: cam1@vcamd1 {
		pins_cmd_dat {
			pins = <PINMUX_GPIO9__FUNC_GPIO9>;
			slew-rate = <1>;
			output-high;
		};
	};*/
        //end, modify by zhijun.fu for  avoid p-sensor interrupt on 2017-12-28
	camera_pins_cam0_mclk_on: camera_pins_cam0_mclk_on {
		pins_cmd_dat {
			pins = <PINMUX_GPIO126__FUNC_CMMCLK0>;
		};
	};
	camera_pins_cam0_mclk_off: camera_pins_cam0_mclk_off {
		pins_cmd_dat {
			pins = <PINMUX_GPIO126__FUNC_GPIO126>;
		};
	};
//Begin modified by zhanyong.yin for XR5301378 on 2017/10/19
	camera_pins_cam1_mclk_on: camera_pins_cam1_mclk_on {
		pins_cmd_dat {
			pins = <PINMUX_GPIO127__FUNC_CMMCLK1>;
		};
	};
	camera_pins_cam1_mclk_off: camera_pins_cam1_mclk_off {
		pins_cmd_dat {
			pins = <PINMUX_GPIO127__FUNC_GPIO127>;
		};
	};
//End modified by zhanyong.yin for XR5301378 on 2017/10/19
	camera_pins_default: camdefault {
	};
};
//Begin added by zhanyong.yin for XR5301378 on 2017/10/19
//begin, modify by zhijun.fu for  imgsensor on 2017-12-28
&kd_camera_hw1 {
	pinctrl-names = "default",
			"cam0_rst0", "cam0_rst1", "cam0_pnd0", "cam0_pnd1",//"cam0_af0", "cam0_af1",
			"cam1_rst0", "cam1_rst1", "cam1_pnd0", "cam1_pnd1",
			//"cam_ldo_sub_vcamd_0", "cam_ldo_sub_vcamd_1",
			"cam0_mclk_on", "cam0_mclk_off",
			"cam1_mclk_on", "cam1_mclk_off";

	pinctrl-0 = <&camera_pins_default>;
	pinctrl-1 = <&camera_pins_cam0_rst0>;
	pinctrl-2 = <&camera_pins_cam0_rst1>;
	pinctrl-3 = <&camera_pins_cam0_pnd0>;
	pinctrl-4 = <&camera_pins_cam0_pnd1>;
	/*pinctrl-5 = <&camera_pins_cam0_af0>;
	pinctrl-6 = <&camera_pins_cam0_af1>;*/
	pinctrl-5 = <&camera_pins_cam1_rst0>;
	pinctrl-6 = <&camera_pins_cam1_rst1>;
	pinctrl-7 = <&camera_pins_cam1_pnd0>;
	pinctrl-8 = <&camera_pins_cam1_pnd1>;
	/*pinctrl-11 = <&camera_pins_cam_ldo_sub_vcamd_0>;
	pinctrl-12 = <&camera_pins_cam_ldo_sub_vcamd_1>;*/
	pinctrl-9 = <&camera_pins_cam0_mclk_on>;
	pinctrl-10 = <&camera_pins_cam0_mclk_off>;
	pinctrl-11 = <&camera_pins_cam1_mclk_on>;
	pinctrl-12 = <&camera_pins_cam1_mclk_off>;
 
	status = "okay";
//end, modify by zhijun.fu for  camera on 2017-12-28
//End added by zhanyong.yin for XR5301378 on 2017/10/19
};
/* CAMERA GPIO end */

/* AUDIO GPIO standardization */
/* Begin Modified by jindong.chen for task 5424730 on 2018/03/08 */
&audgpio {
	pinctrl-names = 
			"aud_clk_mosi_off",
			"aud_clk_mosi_on",
			"aud_dat_miso_off",
			"aud_dat_miso_on",
			"aud_dat_mosi_off",
			"aud_dat_mosi_on",
			"extamp-pullhigh",
			"extamp-pulllow",
			"aud_clk_mosi_pull_high",
			"aud_clk_mosi_pull_low",
			"hac-pullhigh",
			"hac-pulllow";
	pinctrl-0 = <&aud_clk_mosi_off>;
	pinctrl-1 = <&aud_clk_mosi_on>;
	pinctrl-2 = <&aud_dat_miso_off>;
	pinctrl-3 = <&aud_dat_miso_on>;
	pinctrl-4 = <&aud_dat_mosi_off>;
	pinctrl-5 = <&aud_dat_mosi_on>;
	pinctrl-6 = <&aud_pins_extamp_high>;
	pinctrl-7 = <&aud_pins_extamp_low>;
	pinctrl-8 = <&aud_clk_mosi_pull_high>;
	pinctrl-9 = <&aud_clk_mosi_pull_low>;
	status = "okay";
};

&pio {
	aud_clk_mosi_off: aud_clk_mosi_off {
		pins_cmd1_dat {
			pins = <PINMUX_GPIO65__FUNC_GPIO65>;
			input-enable;
			slew-rate = <0>;
			bias-disable;
		};
		/*
		pins_cmd2_dat {
			pins = <PINMUX_GPIO69__FUNC_GPIO69>;
			input-enable;
			slew-rate = <0>;
			bias-disable;
		}; */
	};
	aud_clk_mosi_on: aud_clk_mosi_on {
		pins_cmd1_dat {
			pins = <PINMUX_GPIO65__FUNC_AUD_CLK_MOSI>;
		};
		/*
		pins_cmd2_dat {
			pins = <PINMUX_GPIO69__FUNC_AUD_CLK_MISO>;
		}; */
	};

	aud_dat_miso_off: aud_dat_miso_off {
		pins_cmd1_dat {
			pins = <PINMUX_GPIO67__FUNC_GPIO67>;
			input-enable;
			slew-rate = <0>;
			bias-disable;
		};
		/*
		pins_cmd2_dat {
			pins = <PINMUX_GPIO68__FUNC_GPIO68>;
			input-enable;
			slew-rate = <0>;
			bias-disable;
		}; */
	};

	aud_dat_miso_on: aud_dat_miso_on {
		pins_cmd1_dat {
			pins = <PINMUX_GPIO67__FUNC_AUD_DAT_MISO0>;
		};
		/*
		pins_cmd2_dat {
			pins = <PINMUX_GPIO68__FUNC_AUD_DAT_MISO1>;
		}; */
	};

	aud_dat_mosi_off: aud_dat_mosi_off {
		pins_cmd1_dat {
			pins = <PINMUX_GPIO63__FUNC_GPIO63>;
			input-enable;
			slew-rate = <0>;
			bias-disable;
		};
		/*
		pins_cmd2_dat {
			pins = <PINMUX_GPIO64__FUNC_GPIO64>;
			input-enable;
			slew-rate = <0>;
			bias-disable;
		}; */
	};
	aud_dat_mosi_on: aud_dat_mosi_on {
		pins_cmd1_dat {
			pins = <PINMUX_GPIO63__FUNC_AUD_DAT_MOSI0>;
		};
		/*
		pins_cmd2_dat {
			pins = <PINMUX_GPIO64__FUNC_AUD_DAT_MOSI1>;
		}; */
	};

	aud_pins_extamp_high: audexamphigh {
		pins_cmd_dat {
			pins = <PINMUX_GPIO24__FUNC_GPIO24>;
			slew-rate = <1>;
			output-high;
		};
	};

	aud_pins_extamp_low: audexamplow {
		pins_cmd_dat {
			pins = <PINMUX_GPIO24__FUNC_GPIO24>;
			slew-rate = <0>;
			output-low;
		};
	};

	aud_clk_mosi_pull_high: aud_clk_mosi_pull_high {
		pins_cmd_dat {
			pins = <PINMUX_GPIO65__FUNC_GPIO65>;
			slew-rate = <1>;
			output-high;
		};
	};

	aud_clk_mosi_pull_low: aud_clk_mosi_pull_low {
		pins_cmd_dat {
			pins = <PINMUX_GPIO65__FUNC_GPIO65>;
			slew-rate = <1>;
			output-low;
		};
	};
	
};

/**************** remove original 
&audgpio {
	pinctrl-names = "aud_dat_mosi_off",
			"aud_dat_mosi_on",
			"aud_dat_miso_off",
			"aud_dat_miso_on",
			"extamp-pullhigh",
			"extamp-pulllow";
	pinctrl-0 = <&aud_dat_mosi_off>;
	pinctrl-1 = <&aud_dat_mosi_on>;
	pinctrl-2 = <&aud_dat_miso_off>;
	pinctrl-3 = <&aud_dat_miso_on>;
	pinctrl-4 = <&aud_pins_extamp_high>;
	pinctrl-5 = <&aud_pins_extamp_low>;
	status = "okay";
};

&pio {
	aud_dat_mosi_off: aud_dat_mosi_off {
		pins_cmd1_dat {
			pins = <PINMUX_GPIO63__FUNC_GPIO63>;
			input-enable;
			slew-rate = <0>;
			bias-disable;
		};
		pins_cmd2_dat {
			pins = <PINMUX_GPIO64__FUNC_GPIO64>;
			input-enable;
			slew-rate = <0>;
			bias-disable;
		};
	};

	aud_dat_mosi_on: aud_dat_mosi_on {
		pins_cmd1_dat {
			pins = <PINMUX_GPIO63__FUNC_AUD_DAT_MOSI0>;
		};
		pins_cmd2_dat {
			pins = <PINMUX_GPIO64__FUNC_AUD_DAT_MOSI1>;
		};
	};

	aud_dat_miso_off: aud_dat_miso_off {
		pins_cmd1_dat {
			pins = <PINMUX_GPIO67__FUNC_GPIO67>;
			input-enable;
			slew-rate = <0>;
			bias-disable;
		};
		pins_cmd2_dat {
			pins = <PINMUX_GPIO68__FUNC_GPIO68>;
			input-enable;
			slew-rate = <0>;
			bias-disable;
		};
	};

	aud_dat_miso_on: aud_dat_miso_on {
		pins_cmd1_dat {
			pins = <PINMUX_GPIO67__FUNC_AUD_DAT_MISO0>;
		};
		pins_cmd2_dat {
			pins = <PINMUX_GPIO68__FUNC_AUD_DAT_MISO1>;
		};
	};
	aud_pins_extamp_high: audexamphigh {
		pins_cmd_dat {
			pins = <PINMUX_GPIO24__FUNC_GPIO24>;
			slew-rate = <1>;
			output-high;
		};
	};

	aud_pins_extamp_low: audexamplow {
		pins_cmd_dat {
			pins = <PINMUX_GPIO24__FUNC_GPIO24>;
			slew-rate = <1>;
			output-low;
		};
	};
}; end remove original */

/* End Modified by jindong.cheng for task 5424730 on 2018/03/08 */
/* AUDIO end */

#include <u5a_plus_dt/cust.dtsi>
/*End of this file, DO NOT ADD ANYTHING HERE*/
